# CY8C5868LTI_LP039 register map
File version: 0.1
Registers are 8-bit, read-write, no defined reset value unless marked. A register's access mark holds for its fields unless they carry their own. Offsets are from the block's base; [hi:lo] are bit positions; {n}, {i} and the like mark numbered series; 'fields as' and 'values as' point back to an identical list.

## Comp
Base 0x400043A7
0x00 Comp_Comp_PM_ACT_CFG — Active Power Mode Configuration Register 7
  [3:0] en_cmp — Enable comparator. Populated subsystems are counted from the LSB, for example bit 0 corresponds to comparator 0
0x10 Comp_Comp_PM_STBY_CFG — Standby Power Mode Configuration Register 7
  fields as Comp_Comp_PM_ACT_CFG
0x28B Comp_Comp_TR0 — Comparator Trim Register_TR0
  [4:0] trimA_4_0_ — Sets the trim value to be added to the P-type load for offset calibration
    0=TRIMA_0 (Does not add any offset); {v}=TRIMA_POS_SIDE_{v} (Adds offset of ~{v}mV to the positive side) (v=1..8); {v}=TRIMA_NEG_SIDE_{v-9} (Adds offset of ~{v-10}mV to the negative side) (v=10..18)
0x28C Comp_Comp_TR1 — Comparator Trim Register_TR1
  [4:0] trimB_4_0_ — Sets the trim value to be added to the N-type load for offset calibration
    0=TRIMB_0 (Does not add any offset); {v}=TRIMB_NEG_SIDE_{v} (Adds offset of ~{v}mV to the negative side) (v=1..8); 10=TRIMB_9 (Does not add any offset); {v}=TRIMB_POS_SIDE_{v-10} (Adds offset of ~{v-10}mV to the positive side) (v=11..18)
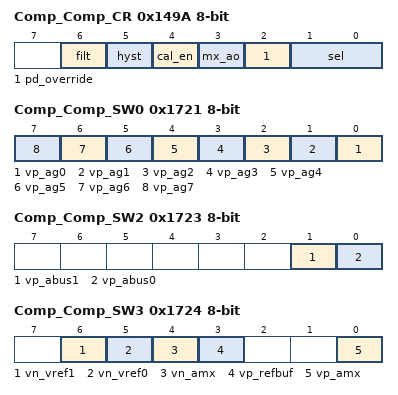
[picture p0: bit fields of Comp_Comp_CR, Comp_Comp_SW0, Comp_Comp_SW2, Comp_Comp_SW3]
0x149A Comp_Comp_CR — Comparator Control Register
  [6] filt — enables a glitch filter at the output of the comparator
    0=FILT_DISABLE (Disable glitch filter); 1=FILT_ENABLE (Enable glitch filter)
  [5] hyst — enables a hysteresis of 10mV typ
    1=HYST_DISABLE (Disable hysteresis); 0=HYST_ENABLE (Enable hysteresis)
  [4] cal_en — enables shorting of the two comparator inputs for trim calibration purposes
    0=CAL_EN_DISABLE (Disable calibration); 1=CAL_EN_ENABLE (Enable calibration)
  [3] mx_ao — comparator sleep always-on logic mux control
    0=MX_AO_BYPASS (Bypass comparator sleep always-on logic); 1=MX_AO_ENABLE (Enable comparator sleep always-on logic)
  [2] pd_override — Power down override to allow comparator to continue operating during sleep
    0=PD_OVERRIDE_DISABLE (Don't override power down); 1=PD_OVERRIDE_ENABLE (Override power down)
  [1:0] sel — Selects the mode of operation of the comparator
    0=SEL_SLOW (slow mode); 1=SEL_FAST (fast mode); 2=SEL_LP (ultra low power mode); 3=SEL_ILLEGAL (Illegal Mode)
0x1721 Comp_Comp_SW0 — Comparator Analog Routing Register 0
  [all] fields
    0=AG_NC (not connected); 1=AG_CONNECTED (Connect to Analog Global)
  [n] vp_ag{n} (n=0..7) — Connect positive voltage input to analog global of same side
0x1723 Comp_Comp_SW2 — Comparator Analog Routing Register 2
  [1] vp_abus1 — Connect positive voltage input to analog (local) bus of the same side
    0=ABUS_NC (not connected); 1=ABUS_CONNECTED (Connect to Analog (local) Bus)
  [0] vp_abus0 — Connect positive voltage input to analog (local) bus of the same side
    values as vp_abus1
0x1724 Comp_Comp_SW3 — Comparator Analog Routing Register 3
  [6] vn_vref1 — Connect negative voltage input to Voltage Reference 1
    0=VREF_NC (not connected); 1=VREF_CONNECTED (Connect to Voltage Reference)
  [5] vn_vref0 — Connect negative voltage input to Voltage Reference 0
    values as vn_vref1
  [4] vn_amx — Connect negative voltage input to Analog Mux Bus
    0=AMX_NC (not connected); 1=AMX_CONNECTED (Connect to AMUXBUS)
  [3] vp_refbuf — Connect positive voltage input to CapSense reference buffer channel
    0=VP_REFBUF_ENABLED (disable); 1=VP_REFBUF_DISABLED (enable)
  [0] vp_amx — Connect positive voltage input to Analog Mux Bus
    values as vn_amx
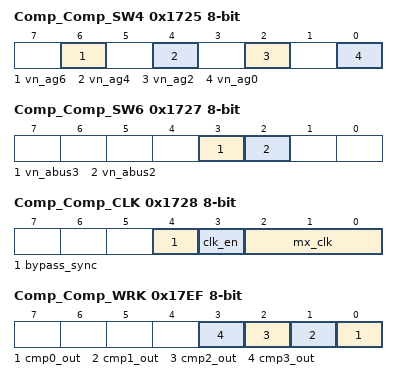
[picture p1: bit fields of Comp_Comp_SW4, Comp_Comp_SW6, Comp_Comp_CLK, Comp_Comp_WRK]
0x1725 Comp_Comp_SW4 — Comparator Analog Routing Register 4
  [all] fields
    values as the fields of Comp_Comp_SW0
  [6] vn_ag6 — Connect negative voltage input to analog global of same side
  [4] vn_ag4 — Connect negative voltage input to analog global of same side
  [2] vn_ag2 — Connect negative voltage input to analog global of same side
  [0] vn_ag0 — Connect negative voltage input to analog global of same side
0x1727 Comp_Comp_SW6 — Comparator Analog Routing Register 6
  [3] vn_abus3 — Connect negative voltage input to analog (local) bus of the same side
    values as Comp_Comp_SW2.vp_abus1
  [2] vn_abus2 — Connect negative voltage input to analog (local) bus of the same side
    values as Comp_Comp_SW2.vp_abus1
0x1728 Comp_Comp_CLK — Comparator Clock Control Register
  [4] bypass_sync — Bypass Synchronization
    0=Synchronization not bypassed (Synchronization enabled); 1=Synchronization bypassed (Synchronization disabled)
  [3] clk_en — Clock gating control
    0=disable clock; 1=enable clock
  [2:0] mx_clk — Clock Selection
    {v}=Select clk_a{v} and clk_a{v}_dig (v=0..3); 4=Select UDB generated clock
0x17EF Comp_Comp_WRK — Comparator output working register
  [n] cmp{n}_out ro (n=0..3) — Comparator Output

## ADC — SAR ADC
Base 0x40004616
0x00 SAR_TR0 — SAR trim register
{0x12F2+i} SAR_CSR{i} (i=0..6) — SAR status and control register {i}
0x1512 SAR_SW0 — SAR Analog Routing Register 0
{0x1512+i} SAR_SW{i} (i=2..4) — SAR Analog Routing Register {i}
0x1518 SAR_SW6 — SAR Analog Routing Register 6
0x1519 SAR_CLK — SAR Clock Selection Register
0x158C SAR_WRK 16-bit — SAR working register

## Airmar — UART
Base 0x4000642B
0x00 RX_Airmar_RX_ADDRESS1 — RX Address1 Register
0x10 RX_Airmar_RX_ADDRESS2 — RX Address2 Register
0x20 RX_Airmar_RX_DATA — RX Data Register
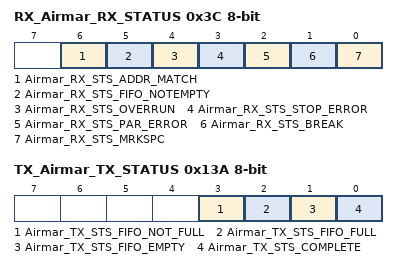
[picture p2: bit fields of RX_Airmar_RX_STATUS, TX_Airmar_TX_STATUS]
0x3C RX_Airmar_RX_STATUS — RX status register
  [6] Airmar_RX_STS_ADDR_MATCH ro, [5] Airmar_RX_STS_FIFO_NOTEMPTY ro, [4] Airmar_RX_STS_OVERRUN ro, [3] Airmar_RX_STS_STOP_ERROR ro, [2] Airmar_RX_STS_PAR_ERROR ro, [1] Airmar_RX_STS_BREAK ro, [0] Airmar_RX_STS_MRKSPC ro
0x11A TX_Airmar_TX_DATA — TX Data Register
0x13A TX_Airmar_TX_STATUS — TX status register
  [3] Airmar_TX_STS_FIFO_NOT_FULL ro, [2] Airmar_TX_STS_FIFO_FULL ro, [1] Airmar_TX_STS_FIFO_EMPTY ro, [0] Airmar_TX_STS_COMPLETE ro
